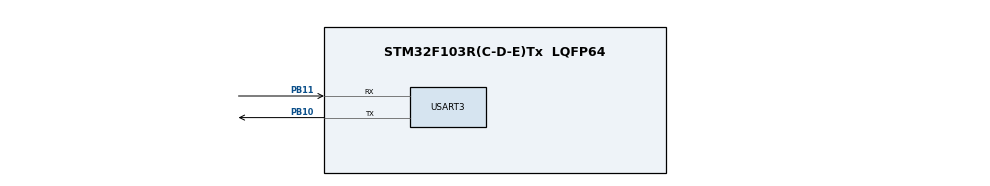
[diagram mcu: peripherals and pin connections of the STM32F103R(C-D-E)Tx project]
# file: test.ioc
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Dma.Request0=USART3_RX
Dma.USART3_RX.0.Direction=DMA_PERIPH_TO_MEMORY
Dma.USART3_RX.0.Instance=DMA1_Channel3
Dma.USART3_RX.0.MemDataAlignment=DMA_MDATAALIGN_BYTE
Dma.USART3_RX.0.MemInc=DMA_MINC_ENABLE
Dma.USART3_RX.0.Mode=DMA_NORMAL
Dma.USART3_RX.0.PeriphDataAlignment=DMA_PDATAALIGN_BYTE
Dma.USART3_RX.0.PeriphInc=DMA_PINC_DISABLE
Dma.USART3_RX.0.Priority=DMA_PRIORITY_LOW
Mcu.Family=STM32F1
Mcu.Name=STM32F103R(C-D-E)Tx
Mcu.Package=LQFP64
NVIC.DMA1_Channel3_IRQn=true\:0\:0\:false\:false\:true\:false\:true
NVIC.PriorityGroup=NVIC_PRIORITYGROUP_4
NVIC.USART3_IRQn=true\:0\:0\:false\:false\:true\:true\:true
PA13.Mode=Serial_Wire
PA13.Signal=SYS_JTMS-SWDIO
PA14.Mode=Serial_Wire
PA14.Signal=SYS_JTCK-SWCLK
PB10.Mode=Asynchronous
PB10.Signal=USART3_TX
PB11.Mode=Asynchronous
PB11.Signal=USART3_RX
PD0-OSC_IN.Mode=HSE-External-Oscillator
PD0-OSC_IN.Signal=RCC_OSC_IN
PD1-OSC_OUT.Mode=HSE-External-Oscillator
PD1-OSC_OUT.Signal=RCC_OSC_OUT
ProjectManager.HeapSize=0x200
ProjectManager.StackSize=0x400
ProjectManager.TargetToolchain=Makefile
RCC.APB1Freq_Value=8000000
RCC.APB2Freq_Value=8000000
USART3.VirtualMode=VM_ASYNC
board=custom

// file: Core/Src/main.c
/* USER CODE BEGIN Header */
/**
  ******************************************************************************
  * @file           : main.c
  * @brief          : Main program body
  ******************************************************************************
  * @attention
  *
  * <h2><center>&copy; Copyright (c) 2021 STMicroelectronics.
  * All rights reserved.</center></h2>
  *
  * This software component is licensed by ST under BSD 3-Clause license,
  * the "License"; You may not use this file except in compliance with the
  * License. You may obtain a copy of the License at:
  *                        opensource.org/licenses/BSD-3-Clause
  *
  ******************************************************************************
  */
/* USER CODE END Header */
#include "main.h"
#include "dma.h"
#include "usart.h"
#include "gpio.h"

/* USER CODE BEGIN Includes */
#include <stdio.h>
/* USER CODE END Includes */

/* USER CODE BEGIN PTD */
extern UART_HandleTypeDef huart3;
/* USER CODE END PTD */

/* USER CODE BEGIN PV */
uint16_t test_cnt = 1;
uint16_t test_cnt2 = 2;
/* USER CODE END PV */

void SystemClock_Config(void);

/* USER CODE BEGIN 0 */
int _io_putchar(char ch)
{
  HAL_UART_Transmit(&huart3,(uint8_t *)&ch,1,10);
  return ch;
}

int _write (int fd, char *pBuffer, int size)
{
  int i;
  for (i = 0; i < size; i++)
  {
    _io_putchar(*pBuffer++);
  }
  return size;
}

/* USER CODE END 0 */

int main(void)
{

  /* MCU Configuration--------------------------------------------------------*/

  /* Reset of all peripherals, Initializes the Flash interface and the Systick. */
  HAL_Init();

  /* Configure the system clock */
  SystemClock_Config();

  /* Initialize all configured peripherals */
  MX_GPIO_Init();
  MX_DMA_Init();
  MX_USART3_UART_Init();

  /* Infinite loop */
  while (1)
  {

    /* USER CODE BEGIN 3 */
    test_cnt ++;
    test_cnt2 = 99;
    HAL_Delay(1000);
    printf("1s test_cnt=%d\r\n",test_cnt);
  }
  /* USER CODE END 3 */
}

void SystemClock_Config(void)
{
  RCC_OscInitTypeDef RCC_OscInitStruct = {0};
  RCC_ClkInitTypeDef RCC_ClkInitStruct = {0};

  /** Initializes the RCC Oscillators according to the specified parameters
  * in the RCC_OscInitTypeDef structure.
  */
  RCC_OscInitStruct.OscillatorType = RCC_OSCILLATORTYPE_HSI;
  RCC_OscInitStruct.HSIState = RCC_HSI_ON;
  RCC_OscInitStruct.HSICalibrationValue = RCC_HSICALIBRATION_DEFAULT;
  RCC_OscInitStruct.PLL.PLLState = RCC_PLL_NONE;
  if (HAL_RCC_OscConfig(&RCC_OscInitStruct) != HAL_OK)
  {
    Error_Handler();
  }
  /** Initializes the CPU, AHB and APB buses clocks
  */
  RCC_ClkInitStruct.ClockType = RCC_CLOCKTYPE_HCLK|RCC_CLOCKTYPE_SYSCLK
                              |RCC_CLOCKTYPE_PCLK1|RCC_CLOCKTYPE_PCLK2;
  RCC_ClkInitStruct.SYSCLKSource = RCC_SYSCLKSOURCE_HSI;
  RCC_ClkInitStruct.AHBCLKDivider = RCC_SYSCLK_DIV1;
  RCC_ClkInitStruct.APB1CLKDivider = RCC_HCLK_DIV1;
  RCC_ClkInitStruct.APB2CLKDivider = RCC_HCLK_DIV1;

  if (HAL_RCC_ClockConfig(&RCC_ClkInitStruct, FLASH_LATENCY_0) != HAL_OK)
  {
    Error_Handler();
  }
}

void Error_Handler(void)
{
  __disable_irq();
  while (1)
  {
  }
}

/************************ (C) COPYRIGHT STMicroelectronics *****END OF FILE****/
